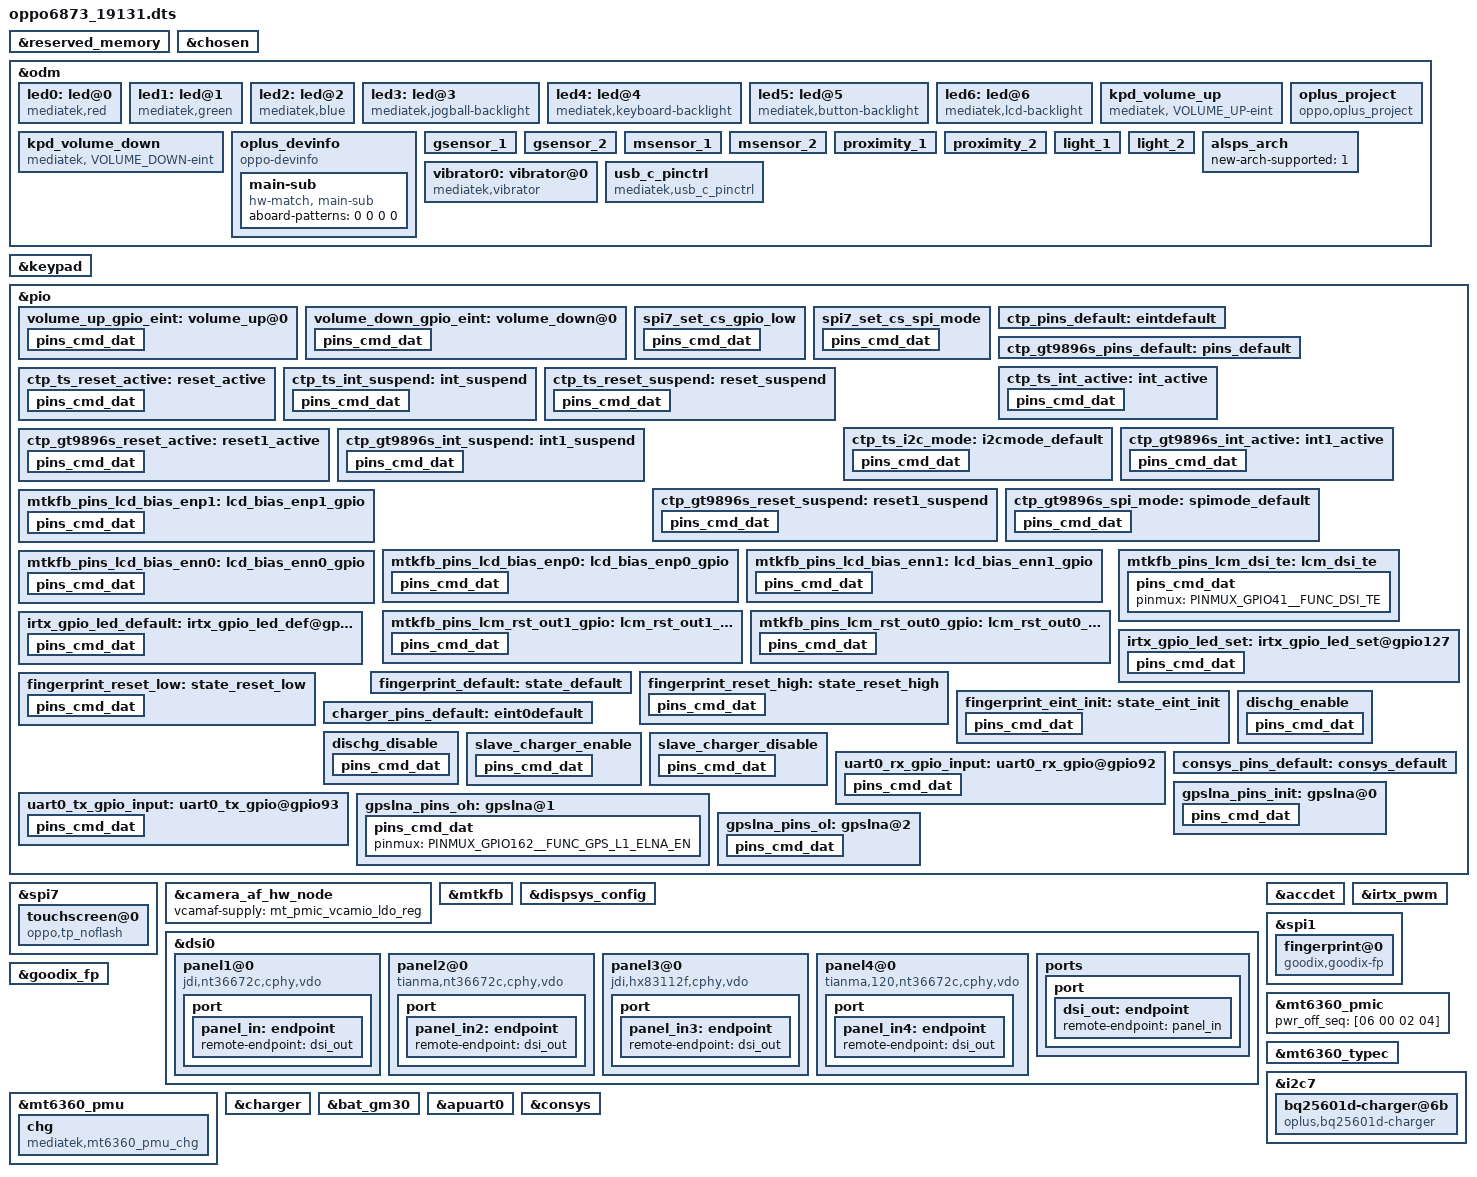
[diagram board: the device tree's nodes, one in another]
/*
 * Mediatek's mt6873 SoC device tree source
 *
 * Copyright (C) 2016 MediaTek Inc.
 *
 * This program is free software; you can redistribute it and/or modify
 * it under the terms of the GNU General Public License version 2 as
 * published by the Free Software Foundation.
 *
 * This program is distributed in the hope that it will be useful,
 * but WITHOUT ANY WARRANTY; without even the implied warranty of
 * MERCHANTABILITY or FITNESS FOR A PARTICULAR PURPOSE.
 * See http://www.gnu.org/licenses/gpl-2.0.html for more details.
 */
/dts-v1/;
/plugin/;
#include <dt-bindings/interrupt-controller/irq.h>
#include <dt-bindings/interrupt-controller/arm-gic.h>
#include <dt-bindings/pinctrl/mt6873-pinfunc.h>

&reserved_memory {
};

/* chosen */
&chosen {

	atag,videolfb-fb_base_l = <0x7e605000>;
	atag,videolfb-fb_base_h = <0x0>;
	atag,videolfb-islcmfound = <1>;
	atag,videolfb-islcm_inited = <0>;
	atag,videolfb-fps= <6000>;
	atag,videolfb-vramSize= <0x1be0000>;
	atag,videolfb-lcmname=
		"nt35595_fhd_dsi_cmd_truly_nt50358_drv";
};

&odm {
	led0:led@0 {
		compatible = "mediatek,red";
		led_mode = <0>;
		data = <1>;
		pwm_config = <0 0 0 0 0>;
	};
	led1:led@1 {
		compatible = "mediatek,green";
		led_mode = <0>;
		data = <1>;
		pwm_config = <0 0 0 0 0>;
	};
	led2:led@2 {
		compatible = "mediatek,blue";
		led_mode = <0>;
		data = <1>;
		pwm_config = <0 0 0 0 0>;
	};
	led3:led@3 {
		compatible = "mediatek,jogball-backlight";
		led_mode = <0>;
		data = <1>;
		pwm_config = <0 0 0 0 0>;
	};
	led4:led@4 {
		compatible = "mediatek,keyboard-backlight";
		led_mode = <0>;
		data = <1>;
		pwm_config = <0 0 0 0 0>;
	};
	led5:led@5 {
		compatible = "mediatek,button-backlight";
		led_mode = <0>;
		data = <1>;
		pwm_config = <0 0 0 0 0>;
	};
	led6:led@6 {
		compatible = "mediatek,lcd-backlight";
		led_mode = <4>;
		data = <1>;
		pwm_config = <0 1 0 0 0>;
	};
/*keypad start*/
	kpd_volume_up:kpd_volume_up {
		compatible = "mediatek, VOLUME_UP-eint";
		interrupt-parent = <&pio>;
		interrupts = <59 IRQ_TYPE_EDGE_FALLING 59 0>;
		debounce = <32000>;
		status = "okay";
	};

	kpd_volume_down:kpd_volume_down {
		compatible = "mediatek, VOLUME_DOWN-eint";
		interrupt-parent = <&pio>;
		interrupts = <155 IRQ_TYPE_EDGE_FALLING 155 0>;
		debounce = <32000>;
		status = "okay";
	};
/*keypad end*/
	oplus_project:oplus_project {
		compatible = "oppo,oplus_project";
	};
	oplus_devinfo:oplus_devinfo {
		compatible = "oppo-devinfo";

		main-sub {
			compatible = "hw-match, main-sub";
			aboard-patterns = <0 0 0 0>;
			/*main board*/
			//match-projects = <20075 20076>;
		};
	};
		 /*
	enum {
		LIS3DH,
		LSM6DS3,
		BMI160,
		LIS2HH12,
		LSM6DSM,
		BMI2XY,
	};
	*/
	gsensor_1: gsensor_1 {
		status = "okay";
		sensor_name = <2>;//BMI160
		i2c_num = <2>;
		i2c_addr = <0>;
		direction = <0>;
		eint_num = <3>;
		step_count_7_en = <1>;
		config_miso = <1>;
		correct_y_bias = <1>;
	};

	gsensor_2: gsensor_2 {
		status = "okay";
		sensor_name = <4>;//LSM6DSM
		i2c_num = <2>;
		i2c_addr = <0>;
		direction = <1>;
		eint_num = <3>;
		step_count_7_en = <1>;
		config_miso = <1>;
		correct_y_bias = <1>;
	};
	/*
	enum {
		AKM09911,
		MMC3530,
		MMC5603,
		MXG4300,
	};
	*/
	msensor_1: msensor_1 {
		status = "okay";
		sensor_name = <0>;//AKM09911
		i2c_num = <0>;
		i2c_addr = <12>;
		direction = <3>;
  		eint_num = <0>;
 		parameter-number= <18>;
 		soft-mag-parameter = <9263 1 322 0 140 0 48 1 10701 1 125 0 103 1 140 1 10726 1>;
	};
	msensor_2: msensor_2 {
		status = "okay";
		sensor_name = <3>;//MXG4300
		i2c_num = <0>;
		i2c_addr = <12>;
		direction = <3>;
		eint_num = <0>;
 		parameter-number= <18>;
 		soft-mag-parameter = <10814 0 210 0 189 0 30 1 9485 0 135 0 117 1 136 0 10658 0>;
	};
	/*
	enum {
		TMD2725,
		APSD9922,
		STK3335,
		STK3331,
		STK2232,
		TCS3701,
		STK32600,
		TCS3408,
		STK33502,
	};
	*/
	proximity_1: proximity_1 {
		status = "okay";
		sensor_name = <8>;//STK33502
		i2c_num = <0>;
		i2c_addr = <70>;
		direction = <4>;
		eint_num = <11>;
		low_step = <300>;
		high_step = <400>;
		low_limit = <650>;
		high_limit = <1050>;
		dirty_low_step = <300>;
		dirty_high_step = <400>;
		ps_dirty_limit = <1800>;
		ps_ir_limit = <2000>;
		ps_adjust_min = <0>;
		ps_adjust_max = <1850>;
		sampling_count = <5>;
		step_max = <400>;
		step_min = <100>;
		step_div = <2000>;
		anti_shake_delta = <70>;
		dynamic_cali_max = <2000>;
		raw2offset_radio = <1000>;
		offset_max = <60000>;
		offset_range_min = <0>;
		offset_range_max = <65534>;
		force_cali_limit = <2000>;
		cali_jitter_limit = <20>;
		cal_offset_margin = <3000>;
	};
	proximity_2: proximity_2 {
		status = "okay";
		sensor_name = <5>;//TCS3701
		i2c_num = <0>;
		i2c_addr = <57>;
		direction = <4>;
		eint_num = <11>;
		low_step = <300>;
		high_step = <400>;
		low_limit = <400>;
		high_limit = <600>;
		dirty_low_step = <180>;
		dirty_high_step = <250>;
		ps_dirty_limit = <1023>;
		ps_ir_limit = <500>;
		ps_adjust_min = <0>;
		ps_adjust_max = <600>;
		sampling_count = <5>;
		step_max = <400>;
		step_min = <110>;
		step_div = <1500>;
		anti_shake_delta = <80>;
		dynamic_cali_max = <1024>;
		raw2offset_radio = <20800>;
		offset_max = <250>;
		offset_range_min = <255>;
		offset_range_max = <255>;
		force_cali_limit = <2000>;
		cali_jitter_limit = <30>;
		cal_offset_margin = <120>;
	};
	light_1: light_1 {
		status = "okay";
		sensor_name = <8>;//STK33502
		i2c_num = <0>;
		i2c_addr = <70>;
		direction = <4>;
		eint_num = <11>;
		als_buffer_length =<8>;
		als_ratio = <65>;
	};
	light_2: light_2 {
		status = "okay";
		sensor_name = <5>;//TCS3701
		i2c_num = <0>;
		i2c_addr = <57>;
		direction = <4>;
		eint_num = <11>;
		als_buffer_length = <10>;
		als_ratio = <110>;
	};
	alsps_arch: alsps_arch {
		status = "okay";
		new-arch-supported = <1>;
	};
	vibrator0:vibrator@0 {
		compatible = "mediatek,vibrator";
		vib_timer = <25>;
		vib_limit = <9>;
		vib_vol= <9>;
	};
	usb_c_pinctrl:usb_c_pinctrl {
		compatible = "mediatek,usb_c_pinctrl";
	};
};

&keypad {
	keypad,volume-up	= <&pio 20 0x00>;
	keypad,volume-down	= <&pio 155 0x00>;
	pinctrl-names = "volume_up_as_int", "volume_down_as_int";
	pinctrl-0 = <&volume_up_gpio_eint>;
	pinctrl-1 = <&volume_down_gpio_eint>;
	status = "okay";
};

&pio {
	volume_up_gpio_eint:volume_up@0{
		pins_cmd_dat {
			pinmux = <PINMUX_GPIO59__FUNC_GPIO59>;
			slew-rate = <0>;  /*direction 0:in, 1:out*/
			input-enable;
		};
	};

	volume_down_gpio_eint:volume_down@0{
		pins_cmd_dat {
			pinmux = <PINMUX_GPIO155__FUNC_GPIO155>;
			slew-rate = <0>;  /*direction 0:in, 1:out*/
			input-enable;
		};
	};
};
/* TOUCH start */
&spi7 {
	status = "okay";
	touchscreen@0 {
		compatible = "oppo,tp_noflash";
		reg = <0>;
		chip-name = "OPPO_TP_NOFLASH";
		status = "ok";

		spi-max-frequency = <9600000>;	//4800000,9600000,15000000,19200000
		interrupt-parent = <&pio>;
		interrupts = <21 IRQ_TYPE_EDGE_FALLING 21 0>;
		irq-gpio = <&pio 21 0x2002>;
		//reset-gpio = <&pio 20 0>;
		//lcd-reset-gpio = <&pio 20 0>;

		platform_support_project = <19131 19132 19133>;
		platform_support_project_dir = <19131 19131 19131>;
		platform_support_project_commandline = "default_commandline","default_commandline","default_commandline";

		touchpanel,max-num-support = <10>;
		touchpanel,tx-rx-num = <16 36>;
		touchpanel,panel-coords = <1080 2400>;
		touchpanel,display-coords = <1080 2400>;
		touchpanel,touchmajor-limit = <0 54>;

		pinctrl-names = "default", "pin_set_low", "pin_set_high";
		pinctrl-0 = <&ctp_gt9896s_int_active &ctp_gt9896s_spi_mode>;
		pinctrl-1 = <&spi7_set_cs_gpio_low &ctp_ts_int_suspend>;
		pinctrl-2 = <&spi7_set_cs_spi_mode &ctp_ts_int_active>;

		incell_screen;
		fw_edge_limit_support;
		black_gesture_support;
		charger_pump_support;
		headset_pump_support;
		esd_handle_support;
		black_gesture_test_support;
		game_switch_support;
		noflash_support;
		lcd_trigger_load_tp_fw_support;
		smart_gesture_support;
		pressure_report_support;
		fw_update_app_support;
		//fw_update_in_probe_with_headfile;

		touchpanel,button-type = <4>;
	};
};


&pio {
	spi7_set_cs_gpio_low: spi7_set_cs_gpio_low {
		pins_cmd_dat {
			pinmux = <PINMUX_GPIO205__FUNC_GPIO205>,
					<PINMUX_GPIO204__FUNC_GPIO204>;
			drive-strength = <5>;
			slew-rate = <1>;
			output-low;
		};
	};
	spi7_set_cs_spi_mode: spi7_set_cs_spi_mode {
		pins_cmd_dat {
			pinmux = <PINMUX_GPIO205__FUNC_SPI7_A_CSB>,
					<PINMUX_GPIO204__FUNC_SPI7_A_CLK>;
			drive-strength = <4>;
			output-high;
		};
	};
	ctp_pins_default: eintdefault {
	};
	ctp_gt9896s_pins_default: pins_default {
	};
	ctp_ts_int_active: int_active {
		pins_cmd_dat {
			pinmux = <PINMUX_GPIO21__FUNC_GPIO21>;
			slew-rate = <0>;
			bias-pull-up = <11>;
		};
	};
	ctp_ts_reset_active: reset_active {
		pins_cmd_dat {
			pinmux = <PINMUX_GPIO20__FUNC_GPIO20>;
			slew-rate = <1>;
			output-high;
		};
	};
	ctp_ts_int_suspend: int_suspend {
		pins_cmd_dat {
			pinmux = <PINMUX_GPIO21__FUNC_GPIO21>;
			slew-rate = <1>;
			output-low;
		};
	};
	ctp_ts_reset_suspend: reset_suspend {
		pins_cmd_dat {
			pinmux = <PINMUX_GPIO20__FUNC_GPIO20>;
			slew-rate = <1>;
			output-low;
		};
	};
	ctp_ts_i2c_mode: i2cmode_default {
		pins_cmd_dat {
			pinmux = <PINMUX_GPIO204__FUNC_SCL0>,
				<PINMUX_GPIO205__FUNC_SDA0>;
			mediatek,drive-strength-adv = <0>;/*EH[2:0]*/
		};
	};
	ctp_gt9896s_int_active: int1_active {
		pins_cmd_dat {
			pinmux = <PINMUX_GPIO21__FUNC_GPIO21>;
			slew-rate = <0>;
			bias-pull-up = <11>;
		};
	};
	ctp_gt9896s_reset_active: reset1_active {
		pins_cmd_dat {
			pinmux = <PINMUX_GPIO20__FUNC_GPIO20>;
			slew-rate = <1>;
			output-high;
		};
	};
	ctp_gt9896s_int_suspend: int1_suspend {
		pins_cmd_dat {
			pinmux = <PINMUX_GPIO21__FUNC_GPIO21>;
			slew-rate = <1>;
			output-low;
		};
	};
	ctp_gt9896s_reset_suspend: reset1_suspend {
		pins_cmd_dat {
			pinmux = <PINMUX_GPIO20__FUNC_GPIO20>;
			slew-rate = <1>;
			output-low;
		};
	};
	ctp_gt9896s_spi_mode: spimode_default {
		pins_cmd_dat {
			pinmux = <PINMUX_GPIO16__FUNC_SPI7_A_MI>,
				<PINMUX_GPIO17__FUNC_SPI7_A_MO>,
				<PINMUX_GPIO204__FUNC_SPI7_A_CLK>,
				<PINMUX_GPIO205__FUNC_SPI7_A_CSB>;
			drive-strength = <4>;
		};
	};
};
/* TOUCH end */

/* DISPSYS GPIO standardization */

&pio {
	mtkfb_pins_lcd_bias_enp1: lcd_bias_enp1_gpio {
		pins_cmd_dat {
			pinmux = <PINMUX_GPIO28__FUNC_GPIO28>;
			slew-rate = <1>;
			output-high;
		};
	};

	mtkfb_pins_lcd_bias_enp0: lcd_bias_enp0_gpio {
		pins_cmd_dat {
			pinmux = <PINMUX_GPIO28__FUNC_GPIO28>;
			slew-rate = <1>;
			output-low;
		};
	};

	mtkfb_pins_lcd_bias_enn1: lcd_bias_enn1_gpio {
		pins_cmd_dat {
			pinmux = <PINMUX_GPIO29__FUNC_GPIO29>;
			slew-rate = <1>;
			output-high;
		};
	};

	mtkfb_pins_lcd_bias_enn0: lcd_bias_enn0_gpio {
		pins_cmd_dat {
			pinmux = <PINMUX_GPIO29__FUNC_GPIO29>;
			slew-rate = <1>;
			output-low;
		};
	};

	mtkfb_pins_lcm_rst_out1_gpio: lcm_rst_out1_gpio {
		pins_cmd_dat {
			pinmux = <PINMUX_GPIO42__FUNC_GPIO42>;
			slew-rate = <1>;
			output-high;
		};
	};

	mtkfb_pins_lcm_rst_out0_gpio: lcm_rst_out0_gpio {
		pins_cmd_dat {
			pinmux = <PINMUX_GPIO42__FUNC_GPIO42>;
			slew-rate = <1>;
			output-low;
		};
	};
	mtkfb_pins_lcm_dsi_te: lcm_dsi_te {
		pins_cmd_dat {
			pinmux = <PINMUX_GPIO41__FUNC_DSI_TE>;
		};
	};
};

&camera_af_hw_node {
	vcamaf-supply = <&mt_pmic_vcamio_ldo_reg>;
	status = "okay";
};

&mtkfb {
	pinctrl-names = "lcd_bias_enp1_gpio", "lcd_bias_enp0_gpio",
		"lcd_bias_enn1_gpio", "lcd_bias_enn0_gpio",
		"lcm_rst_out1_gpio", "lcm_rst_out0_gpio",
		"mode_te_te";
	pinctrl-0 = <&mtkfb_pins_lcd_bias_enp1>;
	pinctrl-1 = <&mtkfb_pins_lcd_bias_enp0>;
	pinctrl-2 = <&mtkfb_pins_lcd_bias_enn1>;
	pinctrl-3 = <&mtkfb_pins_lcd_bias_enn0>;
	pinctrl-4 = <&mtkfb_pins_lcm_rst_out1_gpio>;
	pinctrl-5 = <&mtkfb_pins_lcm_rst_out0_gpio>;
	pinctrl-6 = <&mtkfb_pins_lcm_dsi_te>;
	status = "okay";
};

&dispsys_config {
	pinctrl-names =
		"lcm_rst_out1_gpio", "lcm_rst_out0_gpio",
		"mode_te_te";
	pinctrl-0 = <&mtkfb_pins_lcm_rst_out1_gpio>;
	pinctrl-1 = <&mtkfb_pins_lcm_rst_out0_gpio>;
	pinctrl-2 = <&mtkfb_pins_lcm_dsi_te>;
	status = "okay";
};

&dsi0 {
	status = "okay";
	#address-cells = <1>;
	#size-cells = <0>;
	panel1@0 {
		compatible = "jdi,nt36672c,cphy,vdo";
		reg = <0>;
		pm-enable-gpios = <&pio 41 0>;
		reset-gpios = <&pio 42 0>;
		ldo-gpios = <&pio 27 0>;
		bias-gpios = <&pio 28 0>,
			<&pio 29 0>;
		pinctrl-names = "default";
		port {
			panel_in: endpoint {
				remote-endpoint = <&dsi_out>;
			};
		};
	};
	panel2@0 {
		compatible = "tianma,nt36672c,cphy,vdo";
		reg = <1>;
		pm-enable-gpios = <&pio 41 0>;
		reset-gpios = <&pio 42 0>;
		ldo-gpios = <&pio 27 0>;
		bias-gpios = <&pio 28 0>,
			<&pio 29 0>;
		pinctrl-names = "default";
		port {
			panel_in2: endpoint {
				remote-endpoint = <&dsi_out>;
			};
		};
	};
	panel3@0 {
		compatible = "jdi,hx83112f,cphy,vdo";
		reg = <2>;
		pm-enable-gpios = <&pio 41 0>;
		reset-gpios = <&pio 42 0>;
		ldo-gpios = <&pio 27 0>;
		bias-gpios = <&pio 28 0>,
			<&pio 29 0>;
		pinctrl-names = "default";
		port {
			panel_in3: endpoint {
				remote-endpoint = <&dsi_out>;
			};
		};
	};
	panel4@0 {
		compatible = "tianma,120,nt36672c,cphy,vdo";
		reg = <3>;
		pm-enable-gpios = <&pio 41 0>;
		reset-gpios = <&pio 42 0>;
		ldo-gpios = <&pio 27 0>;
		bias-gpios = <&pio 28 0>,
			<&pio 29 0>;
		pinctrl-names = "default";
		port {
			panel_in4: endpoint {
				remote-endpoint = <&dsi_out>;
			};
		};
	};
	ports {
		port {
			dsi_out: endpoint {
				remote-endpoint = <&panel_in>;
			};
		};
	};
};

/* accdet start */
&accdet {
	/* accdet micbias voltage: 0x09:2.85v 0x08:2.8v 0x07,
	 * 2.7v;0x05,2.5v;0x02,1.9v
	 */
	accdet-mic-vol = <8>;
	/* accdet pwm_width, pwm_thresh, fall_delay, rise_delay
	 * debounce0, debounce1, debounce3, debounce4
	 * eint pwm_width, eint pwm_thresh
	 * eint deb(debounce0, debounce1, debounce2, debounce3), inv_debounce
	 */
	headset-mode-setting = <0x500 0x500 1 0x1f0
				0x800 0x800 0x20 0x44
				0x4 0x1
				0x5 0x3 0x3 0x5 0xe>;
	accdet-plugout-debounce = <1>;
	/*1:ACC mode, 2:low cost without in bias, 6:low cost with in bias*/
	accdet-mic-mode = <2>;
	/*0--MD_MAX--UP_MAX--DW_MAX*/
	headset-three-key-threshold = <0 80 220 400>;
	headset-three-key-threshold-CDD = <0 121 192 600>;
	/*0--MD_MAX--VOICE_MAX--UP_MAX--DW_MAX*/
	headset-four-key-threshold = <0 58 121 192 400>;

	/* select VTH to 2v and 500k, use internal resitance */
	eint_use_ext_res = <0>;
	status = "okay";
};
/* accdet end */

/* IRTX GPIO Start */
&irtx_pwm {
	pinctrl-names = "irtx_gpio_led_default", "irtx_gpio_led_set";
	pinctrl-0 = <&irtx_gpio_led_default>;
	pinctrl-1 = <&irtx_gpio_led_set>;
	status = "okay";
};
&pio {
	/* IRTX GPIO Settings -Start */
	/* default: GPIO0, output, high */
	irtx_gpio_led_default:irtx_gpio_led_def@gpio127 {
		pins_cmd_dat {
			pinmux = <PINMUX_GPIO127__FUNC_GPIO127>;
			slew-rate = <1>;
			bias-disable;
			output-low;
			input-schmitt-enable = <0>;
		};
	};

	irtx_gpio_led_set:irtx_gpio_led_set@gpio127 {
		pins_cmd_dat {
			pinmux = <PINMUX_GPIO127__FUNC_PWM_3>;
			slew-rate = <1>;
			output-high;
		};
	};
}; /* IRTX GPIO Settings -End */

/* FINGERPRINT start */
&spi1 {
	#address-cells = <1>;
	#size-cells = <0>;
	fingerprint@0 {
		compatible = "goodix,goodix-fp";
		reg = <0>;
		spi-max-frequency = <8000000>;
		netlink-event = <30>;
		vfp-supply = <&mt_pmic_vfp_ldo_reg>;
		power-type = <1>;
		status = "okay";
	};
};

&goodix_fp {
	pinctrl-names = "default", "reset_high", "reset_low", "eint_init";
	pinctrl-0 = <&fingerprint_default>;
	pinctrl-1 = <&fingerprint_reset_high>;
	pinctrl-2 = <&fingerprint_reset_low>;
	pinctrl-3 = <&fingerprint_eint_init>;
	interrupt-parent = <&pio>;
	interrupts = <15 IRQ_TYPE_EDGE_RISING 15 0>;
	status = "okay";
};

&pio {
	fingerprint_default: state_default {
	};
	fingerprint_reset_high: state_reset_high {
		pins_cmd_dat {
			pinmux = <PINMUX_GPIO14__FUNC_GPIO14>;
			slew-rate = <1>;
			output-high;
		};
	};
	fingerprint_reset_low: state_reset_low {
		pins_cmd_dat {
			pinmux = <PINMUX_GPIO14__FUNC_GPIO14>;
			slew-rate = <1>;
			output-low;
		};
	};
	fingerprint_eint_init: state_eint_init {
		pins_cmd_dat {
			pinmux = <PINMUX_GPIO15__FUNC_GPIO15>;
			slew-rate = <0>;
			bias-pull-up = <MTK_PUPD_SET_R1R0_10>;
			input-schmitt-enable;
		};
	};
};
/* FINGERPRINT end */

/* Charging Start */

&mt6360_pmu {
	mt6360,intr_gpio_num = <24>; /* direct defined GPIO num */
	mt6360,intr_gpio = <&pio 24 0x0>;
};

&mt6360_pmic {
	pwr_off_seq = [06 00 02 04];
};

&mt6360_typec {
	mt6360pd,intr_gpio_num = <25>; /* direct defined GPIO num */
	mt6360pd,intr_gpio = <&pio 25 0x0>;
};

&mt6360_pmu {
	chg {
		compatible = "mediatek,mt6360_pmu_chg";
		interrupt-parent = <&mt6360_pmu>;
		interrupts = <4 0>, <6 0>, <7 0>, <9 0>,
				<12 0>, <13 0>, <14 0>, <15 0>,
				<27 0>, <29 0>, <30 0>, <32 0>,
				<35 0>, <40 0>, <48 0>, <60 0>,
				<53 0>;
		interrupt-names = "chg_treg_evt", "chg_mivr_evt",
				"pwr_rdy_evt", "chg_batsysuv_evt",
				"chg_vsysuv_evt", "chg_vsysov_evt",
				"chg_vbatov_evt", "chg_vbusov_evt",
				"chg_tmri", "chg_adpbadi",
				"chg_rvpi",  "chg_aiccmeasl",
				"wdtmri", "pumpx_donei",
				"attachi", "chrdet_ext_evt",
				"hvdcp_det";
		io-channels = <&adc 0>, <&adc 1>, <&adc 3>, <&adc 4>,
				<&adc 5>, <&adc 6>, <&adc 8>, <&adc 10>;
		io-channel-names = "USBID", "VBUSDIV5", "VSYS", "VBAT",
				"IBUS", "IBAT", "TEMP_JC", "TS";
		chg_name = "primary_chg";
		ichg = <2000000>;               /* uA */
		aicr = <500000>;                /* uA */
		mivr = <4400000>;               /* uV */
		cv = <4350000>;                 /* uA */
		ieoc = <150000>;                /* uA */
		safety_timer = <12>;            /* hour */
		ircmp_resistor = <25000>;       /* uohm */
		ircmp_vclamp = <32000>;         /* uV */
		en_te = <1>;
		en_wdt = <1>;
		aicc_once = <1>;
		post_aicc = <1>;
		batoc_notify = <0>;
	};
};

&i2c7 {
	bq25601d-charger@6b {
		status = "okay";
		compatible = "oplus,bq25601d-charger";
		reg = <0x6b>;
		chip-name = "BQ25601D";
		interrupt-parent = <&pio>;
		interrupts = <12 IRQ_TYPE_EDGE_FALLING 12 0>;
		chg-irq-gpio = <&pio 12 0x2002>;

		pinctrl-names = "slave_charger_enable", "slave_charger_disable";
		pinctrl-0 = <&slave_charger_enable>;
                pinctrl-1 = <&slave_charger_disable>;

		qcom,slave-chg-en-gpio = <&pio 2 0x00>;
	};
};

&charger {
	io-channels = <&auxadc 4>,
		<&auxadc 5>;
	io-channel-names = "auxadc4-usb_temp_v_l",
		"auxadc5-usb_temp_v_r";

	pinctrl-names = "default", "dischg_enable", "dischg_disable";
	pinctrl-0 = <&charger_pins_default>;
	pinctrl-1 = <&dischg_enable>;
	pinctrl-2 = <&dischg_disable>;

	//for oplus chg framework:
	qcom,input_current_charger_ma = <2000>;
        qcom,input_current_usb_ma = <500>;
        qcom,input_current_cdp_ma = <1500>;
        qcom,input_current_led_ma = <1200>;
        qcom,input_current_led_ma_high = <1000>;
        qcom,input_current_led_ma_warm = <1500>;
        qcom,input_current_led_ma_normal = <2000>;
        qcom,input_current_led_ma_forcmcc = <500>;
        qcom,input_current_camera_ma = <2000>;
        qcom,input_current_calling_ma = <1200>;
        qcom,qc_input_current_charger_ma = <2000>;

	qcom,iterm_disabled = <0>;
	qcom,iterm_ma = <200>;
	qcom,recharge-mv = <100>;

	qcom,batt_capacity_mah = <3900>;

	qcom,removed_bat_decidegc = <190>;  /* < -19C */

	qcom,cold_bat_decidegc = <20>;  /* -2C ~ 0C */
        qcom,temp_cold_vfloat_mv = <3980>;
        qcom,temp_cold_fastchg_current_ma = <300>;

        qcom,little_cold_bat_decidegc = <0>;    /* 0C ~ 5C */
        qcom,temp_little_cold_vfloat_mv = <4385>;
        qcom,temp_little_cold_fastchg_current_ma_high = <500>;
        qcom,temp_little_cold_fastchg_current_ma_low = <500>;
        qcom,temp_little_cold_fastchg_current_ma = <600>;
        qcom,qc_temp_little_cold_fastchg_current_ma_high = <500>;
        qcom,qc_temp_little_cold_fastchg_current_ma_low = <500>;

	qcom,cool_bat_decidegc = <50>;  /* 5C ~ 12C */
        qcom,temp_cool_vfloat_mv = <4385>;
        qcom,temp_cool_fastchg_current_ma_high = <1100>;
        qcom,temp_cool_fastchg_current_ma_low = <500>;
        qcom,qc_temp_cool_fastchg_current_ma_high = <1100>;
        qcom,qc_temp_cool_fastchg_current_ma_low = <500>;

        qcom,little_cool_bat_decidegc = <120>;  /* 12C ~ 16C */
        qcom,temp_little_cool_vfloat_mv = <4385>;
        qcom,temp_little_cool_fastchg_current_ma = <1700>;
        qcom,qc_temp_little_cool_fastchg_current_ma = <1700>;

        qcom,normal_bat_decidegc = <160>;       /* 16C ~ 45C */
        qcom,temp_normal_fastchg_current_ma = <2100>;
        qcom,temp_normal_vfloat_mv = <4385>;
        qcom,qc_temp_normal_fastchg_current_ma = <2000>;

        qcom,normal_phase1_bat_decidegc = <160>;       /* 16C ~ 22C */
        qcom,temp_normal_phase1_vfloat_mv = <4385>;
        qcom,temp_normal_phase1_fastchg_current_ma = <2320>;

        qcom,normal_phase2_bat_decidegc = <220>;       /* 22C ~ 34C */
        qcom,temp_normal_phase2_vfloat_mv = <4385>;
        qcom,temp_normal_phase2_fastchg_current_ma_high = <3160>;
        qcom,temp_normal_phase2_fastchg_current_ma_low = <2480>;

        qcom,normal_phase3_bat_decidegc = <340>;       /* 34 ~ 37C */
        qcom,temp_normal_phase3_vfloat_mv = <4385>;
        qcom,temp_normal_phase3_fastchg_current_ma_high = <2960>;
        qcom,temp_normal_phase3_fastchg_current_ma_low = <2480>;

        qcom,normal_phase4_bat_decidegc = <370>;       /* 37C ~ 40C */
        qcom,temp_normal_phase4_vfloat_mv = <4385>;
        qcom,temp_normal_phase4_fastchg_current_ma_high = <2580>;
        qcom,temp_normal_phase4_fastchg_current_ma_low = <2380>;

        qcom,normal_phase5_bat_decidegc = <400>;       /* 40C ~ 45C */
        qcom,temp_normal_phase5_vfloat_mv = <4385>;
        qcom,temp_normal_phase5_fastchg_current_ma = <2120>;

        qcom,warm_bat_decidegc = <450>;         /* 45C ~ 53C */ /*8pin Bat Vooc project need add 3 degree C*/
        qcom,temp_warm_vfloat_mv = <4130>;
        qcom,temp_warm_fastchg_current_ma = <1100>;
        qcom,temp_warm_fastchg_current_ma_led_on = <500>;
        qcom,qc_temp_warm_fastchg_current_ma = <1100>;

	qcom,hot_bat_decidegc = <530>;  /* > 53C */

	qcom,non_standard_vfloat_mv = <3980>;
	qcom,non_standard_fastchg_current_ma = <512>;

	qcom,short_c_bat_cv_mv = <4330>;
	qcom,short_c_bat_vfloat_mv = <3800>;
	qcom,short_c_bat_fastchg_current_ma = <512>;
	qcom,short_c_bat_vfloat_sw_limit = <3750>;

	qcom,cold_vfloat_sw_limit = <3930>;
	qcom,little_cold_vfloat_sw_limit = <4320>;
	qcom,cool_vfloat_sw_limit = <4320>;
	qcom,little_cool_vfloat_sw_limit = <4320>;
	qcom,normal_vfloat_sw_limit = <4320>;
	qcom,warm_vfloat_sw_limit = <4030>;
	qcom,non_standard_vfloat_sw_limit = <3930>;

	qcom,max_chg_time_sec = <36000>;
	qcom,charger_hv_thr = <10000>;
	qcom,charger_recv_thr = <9700>;
	qcom,charger_lv_thr = <3400>;
	qcom,vbatt_full_thr = <4400>;
	qcom,vbatt_hv_thr = <4500>;

	qcom,vfloat_step_mv = <16>;
	qcom,non_standard_vfloat_over_sw_limit = <3980>;
	qcom,cold_vfloat_over_sw_limit = <3980>;
	qcom,little_cold_vfloat_over_sw_limit = <4390>;
	qcom,cool_vfloat_over_sw_limit = <4390>;
	qcom,little_cool_vfloat_over_sw_limit = <4390>;
	qcom,normal_vfloat_over_sw_limit = <4390>;
	qcom,warm_vfloat_over_sw_limit = <4080>;

	qcom,vbatt_power_off = <3300>;
	qcom,vbatt_soc_1 = <3410>;
	//qcom,vooc_project = <1>;
	qcom,vbatt_num = <1>;

	qcom,normal_vterm_hw_inc = <18>;
	qcom,non_normal_vterm_hw_inc = <18>;

	qcom,overchg_normal_fastchg_ma = <700>;/*16C~35c*/
	qcom,overchg_temp_warm_decidegc = <350>;
	qcom,overchg_warm_fastchg_ma = <750>;/*35C~40c*/
	qcom,overchg_temp_high_decidegc = <400>;

	qcom,overchg_normal_vfloat_sw_limit = <4450>;
	qcom,overchg_temp_normal_vfloat_mv = <4500>;
	qcom,overchg_normal_vfloat_over_sw_limit = <4500>;

	qcom,default_iterm_ma = <200>;
	qcom,default_temp_normal_fastchg_current_ma = <2000>;
	qcom,default_normal_vfloat_sw_limit = <4320>;
	qcom,default_temp_normal_vfloat_mv = <4385>;
	qcom,default_normal_vfloat_over_sw_limit = <4390>;

	//for control:
	//qcom,suspend_after_full;
	qcom,check_batt_full_by_sw;
	qcom,external_gauge;
	qcom,chg_ctrl_by_calling;
	qcom,chg_ctrl_by_lcd;
	qcom,chg_ctrl_by_camera;
	qcom,sw_vfloat_over_protect_enable;

	//for PD9V or QC9V
	qcom,vbatt_pdqc_to_5v_thr = <3400>;
	qcom,dual_charger_support = <1>;
	qcom,slave_pct = <30>;
	qcom,slave_chg_enable_ma = <2100>;
	qcom,slave_chg_disable_ma = <1700>;

	//for step charger
	qcom,step1_time = <300>;		/*5min*/
	qcom,step1_current_ma = <3160>;		/*3200ma*/
	qcom,step2_time = <900>;		/*5min*/
	qcom,step2_current_ma = <2900>;		/*3000ma*/
	qcom,step3_current_ma = <2640>;		/*3000ma*/

	//GPIO config:
	qcom,dischg-gpio = <&pio 54 0x00>;
};

&bat_gm30 {
       FUELGAGUE_APPLY = <(1)>;
};

&pio {
	charger_pins_default: eint0default {
	};

	dischg_enable: dischg_enable {
		pins_cmd_dat {
			pinmux = <PINMUX_GPIO54__FUNC_GPIO54>;
			slew-rate = <1>;//0:input direction 1:output direction
			//bias-pull-up = <00>;
			output-high;
		};
	};

	dischg_disable: dischg_disable {
		pins_cmd_dat {
			pinmux = <PINMUX_GPIO54__FUNC_GPIO54>;
			slew-rate = <1>;
			//bias-pull-down = <00>;
			output-low;
		};
	};

	slave_charger_enable: slave_charger_enable {
                pins_cmd_dat {
                        pinmux = <PINMUX_GPIO2__FUNC_GPIO2>;
                        slew-rate = <1>;//0:input direction 1:output direction
                        bias-pull-up = <00>;
                        output-low;
                };
        };

        slave_charger_disable: slave_charger_disable {
                pins_cmd_dat {
                        pinmux = <PINMUX_GPIO2__FUNC_GPIO2>;
                        slew-rate = <1>;
                        bias-pull-down = <00>;
                        output-high;
                };
        };

};

//#ifdef VENDOR_EDIT
&apuart0 {
	pinctrl-names = "uart0_rx_gpio",
			"uart0_tx_gpio";
	pinctrl-0 = <&uart0_rx_gpio_input>;
	pinctrl-1 = <&uart0_tx_gpio_input>;
	status = "okay";
};

&pio {
	uart0_rx_gpio_input:uart0_rx_gpio@gpio92 {
		pins_cmd_dat {
			pinmux = <PINMUX_GPIO92__FUNC_GPIO92>;
			input-enable;
			slew-rate = <0>;
			bias-disable;
		};
	};
	uart0_tx_gpio_input:uart0_tx_gpio@gpio93 {
		pins_cmd_dat {
			pinmux = <PINMUX_GPIO93__FUNC_GPIO93>;
			input-enable;
			slew-rate = <0>;
			bias-disable;
		};
	};
};
//#endif /* VENDOR_EDIT */

/* &pio {
	charging_switch1_active: charging_switch1_active {
		pins_cmd_dat {
			pinmux = <PINMUX_GPIO191__FUNC_GPIO191>;
			slew-rate = <1>;
			output-high;
		};
	};

	charging_switch1_sleep: charging_switch1_sleep {
		pins_cmd_dat {
			pinmux = <PINMUX_GPIO191__FUNC_GPIO191>;
			slew-rate = <1>;
			output-low;
		};
	};

};*/

//#endif /* VENDOR_EDIT */

/* Charging end  */

/* USB SWITCH GPIO start */
//&pio {
//	usb_default: usb_default {
//	};

//	gpio_redriver_c1_init: c1_init {
//		pins_cmd_dat {
//			pinmux = <PINMUX_GPIO113__FUNC_GPIO113>;
//			slew-rate = <1>;
//			output-low;
//		};
//	};

//	gpio_redriver_c1_low: c1_low {
//		pins_cmd_dat {
//			pinmux = <PINMUX_GPIO113__FUNC_GPIO113>;
//			slew-rate = <1>;
//			output-low;
//		};
//	};

//	gpio_redriver_c1_hiz: c1_highz {
//		pins_cmd_dat {
//			pinmux = <PINMUX_GPIO113__FUNC_GPIO113>;
//			slew-rate= <0>;
//			bias-disable;
//		};
//	};

//	gpio_redriver_c1_high: c1_high {
//		pins_cmd_dat {
//			pinmux = <PINMUX_GPIO113__FUNC_GPIO113>;
//			slew-rate = <1>;
//			output-high;
//		};
//	};

//	gpio_redriver_c2_init: c2_init {
//		pins_cmd_dat {
//			pinmux = <PINMUX_GPIO112__FUNC_GPIO112>;
//			slew-rate = <1>;
//			output-low;
//		};
//	};

//	gpio_redriver_c2_low: c2_low {
//		pins_cmd_dat {
//			pinmux = <PINMUX_GPIO112__FUNC_GPIO112>;
//			slew-rate = <1>;
//			output-low;
//		};
//	};

//	gpio_redriver_c2_hiz: c2_highz {
//		pins_cmd_dat {
//			pinmux = <PINMUX_GPIO112__FUNC_GPIO112>;
//			slew-rate= <0>;
//			bias-disable;
//		};
//	};

//	gpio_redriver_c2_high: c2_high {
//		pins_cmd_dat {
//			pinmux = <PINMUX_GPIO112__FUNC_GPIO112>;
//			slew-rate = <1>;
//			output-high;
//		};
//	};

//	gpio_u3_switch_sel1: u3_sw_sel1 {
//		pins_cmd_dat {
//			pinmux = <PINMUX_GPIO111__FUNC_GPIO111>;
//			slew-rate = <1>;
//			output-low;
//		};
//	};

//	gpio_u3_switch_sel2: u3_sw_sel2 {
//		pins_cmd_dat {
//			pinmux = <PINMUX_GPIO111__FUNC_GPIO111>;
//			slew-rate = <1>;
//			output-high;
//		};
//	};

//	gpio_u3_switch_enable: u3_sw_en {
//	};

//	gpio_u3_switch_disable: u3_sw_dis {
//	};
//};

//&usb_c_pinctrl {
//	pinctrl-names = "usb_default",
//		"redrv_c1_init",
//		"redrv_c1_low",
//		"redrv_c1_hiz",
//		"redrv_c1_high",
//		"redrv_c2_init",
//		"redrv_c2_low",
//		"redrv_c2_hiz",
//		"redrv_c2_high",
//		"switch_sel1",
//		"switch_sel2",
//		"switch_enable",
//		"switch_disable";
//
//	pinctrl-0 = <&usb_default>;
//	pinctrl-1 = <&gpio_redriver_c1_init>;
//	pinctrl-2 = <&gpio_redriver_c1_low>;
//	pinctrl-3 = <&gpio_redriver_c1_hiz>;
//	pinctrl-4 = <&gpio_redriver_c1_high>;
//	pinctrl-5 = <&gpio_redriver_c2_init>;
//	pinctrl-6 = <&gpio_redriver_c2_low>;
//	pinctrl-7 = <&gpio_redriver_c2_hiz>;
//	pinctrl-8 = <&gpio_redriver_c2_high>;
//	pinctrl-9 = <&gpio_u3_switch_sel1>;
//	pinctrl-10 = <&gpio_u3_switch_sel2>;
//	pinctrl-11 = <&gpio_u3_switch_enable>;
//	pinctrl-12 = <&gpio_u3_switch_disable>;
//	status = "okay";
//
//	usb_switch-data {
//		en_pin_num = <0>;
//		en_pin_val = <0>;
//		sel_pin_num = <111>;
//		sel_pin_val = <1>;
//		c1_pin_num = <113>;
//		c1_pin_val = <2>;
//		c2_pin_num = <112>;
//		c2_pin_val = <1>;
//	};
//};
//#endif
/* USB SWITCH GPIO end */

/* battery start */
&bat_gm30 {
	R_FG_VALUE = <(10)>;
};
/* battery end */

/* CONSYS GPIO standardization */
&pio {
	consys_pins_default: consys_default {
	};
	gpslna_pins_init: gpslna@0 {
		pins_cmd_dat {
			pinmux = <PINMUX_GPIO162__FUNC_GPIO162>;
			output-low;
		};
	};
	gpslna_pins_oh: gpslna@1 {
		pins_cmd_dat {
			pinmux = <PINMUX_GPIO162__FUNC_GPS_L1_ELNA_EN>;
		};
	};
	gpslna_pins_ol: gpslna@2 {
		pins_cmd_dat {
			pinmux = <PINMUX_GPIO162__FUNC_GPIO162>;
			output-low;
		};
	};
};
&consys {
	pinctrl-names = "default", "gps_lna_state_init",
		"gps_lna_state_oh", "gps_lna_state_ol";
	pinctrl-0 = <&consys_pins_default>;
	pinctrl-1 = <&gpslna_pins_init>;
	pinctrl-2 = <&gpslna_pins_oh>;
	pinctrl-3 = <&gpslna_pins_ol>;
	status = "okay";
};
/* CONSYS end */

#include "mediatek/cust_mt6873_camera.dtsi"
//#include "mediatek/cust_mt6873_touch_1080x2280.dtsi"
#include <oppo6873_19131/cust.dtsi>
/*End of this file, DO NOT ADD ANYTHING HERE*/
